# AE402FA0E5597BE0_CM55_HE_View register map
Vendor: Alif Semiconductor; Series: E4; File version: 1.0
CPU: CM55 r1p0, selectable endian, MPU, FPU, double-precision FPU, DSP, VTOR, 8 interrupt priority bits, 1 SAU regions
Registers are 32-bit, read-write, reset 0x0 unless marked. A register's access mark holds for its fields unless they carry their own. Offsets are from the block's base; [hi:lo] are bit positions; lines under a group give offsets from that group; {n}, {i} and the like mark numbered series; 'fields as' and 'values as' point back to an identical list.

## DMA2_SEC
Base 0x400C0000
Same registers: DMA2_NS 0x400E0000, DMA0_SEC 0x49080000, DMA0_NS 0x490A0000
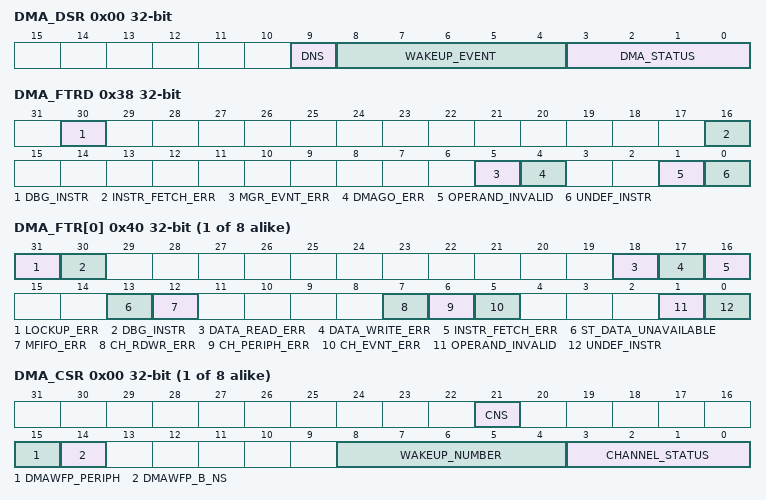
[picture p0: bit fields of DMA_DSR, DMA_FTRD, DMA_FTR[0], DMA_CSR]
0x00 DMA_DSR ro — DMA Manager Status Register
  [9] DNS — This bit provides the security status of the DMA manager thread.
    0=DMA manager operates in the secure state; 1=DMA manager operates in the non-secure state
  [8:4] WAKEUP_EVENT — When the DMA manager thread executes a DMAWFE instruction, it waits for the following event to occur:
    0=event[0]; 1=event[1]; 2=event[2]; 31=event[31]
  [3:0] DMA_STATUS — This bit field presents the operating state of the DMA manager. For more information, see Section Thread Operating States.
    0=Stopped; 1=Executing; 2=Cache miss; 3=Updating PC; 4=Waiting for event; 15=Faulting
0x04 DMA_DPC ro — DMA Program Counter Register
  [31:0] PC_MGR — Program counter for the DMA manager thread.
0x20 DMA_INTEN — Interrupt Enable Register
  [31:0] EVENT_IRQ_SELECT — Program the appropriate bit to control how the DMAC responds when it executes DMASEV. Bit [N] = 0x0: If the DMAC executes DMASEV for the event-interrupt resource N then the DMAC signals event N to all of the threads. Bit [N] = 0x1: If the DMAC executes DMASEV for the event-interrupt resource N then the DMAC sets IRQ[N] high. Note: For more information about selecting an event number, see Section DMASEV.
0x24 DMA_INT_EVENT_RIS ro — Event-Interrupt Raw Status Register
  [31:0] DMASEV_ACTIVE — This bit field returns the status of the event-interrupt resources. - Bit [N] = 0x0: Event N is inactive or IRQ[N] is low. - Bit [N] = 0x1: Event N is active or IRQ[N] is high. Note: When the DMAC executes a DMASEV N instruction to send event N, the DMA_INTEN register controls whether the DMAC: - Signals an interrupt using the appropriate IRQ. - Sends the event to all of the threads (see DMA_INTEN register). Note: The DMAC clears bit [N] when either: - The DMA_INTEN register is programmed to process the event and the DMAC executes a DMAWFE instruction for that event. - The DMA_INTEN register is programmed to signal an interrupt and the user write to the corresponding bit in the DMA_INTCLR register.
0x28 DMA_INTMIS ro — Interrupt Status Register
  [31:0] IRQ_STATUS — This bit field provides the status of the interrupts that are active in the DMAC. - Bit [N] = 0x0: Interrupt N is inactive and therefore IRQ[N] is low. - Bit [N] = 0x1: Interrupt N is active and therefore IRQ[N] is high. Note: User must use the DMA_INTCLR register to set bit [N] to 0x0. Note: Bit [N] is 0x0 if the DMA_INTEN register programs DMASEV to signal an event.
0x2C DMA_INTCLR wo — Interrupt Clear Register
  [31:0] IRQ_CLR — Controls the clearing of the IRQ outputs: - Bit [N] = 0x0: The status of IRQ[N] does not change. - Bit [N] = 0x1: The DMAC sets IRQ[N] low if the DMA_INTEN register programs the DMAC to signal an interrupt. Otherwise, the status of IRQ[N] does not change (see DMA_INTEN register).
0x30 DMA_FSRD ro — Fault Status DMA Manager Register
  [0] FS_MGR — This bit provides the fault status of the DMA manager. Refer to the DMA_FTRD register for more information about the type of fault that occured.
    0=The DMA manager thread is not in the Faulting state; 1=The DMA manager thread is in the Faulting state
0x34 DMA_FSRC ro — Fault Status DMA Channel Register
  [7:0] FAULT_STATUS — Each bit provides the fault status of the corresponding channel. - Bit [N] = 0x0: No fault is present on DMA channel N. - Bit [N] = 0x1: DMA channel N is in the Faulting or Faulting completing state. Refer to the DMA_FTRD register for more information about the type of fault that occured.
0x38 DMA_FTRD ro — Fault Type DMA Manager Register
  [30] DBG_INSTR — If the DMA manager aborts, this bit indicates whether the erroneous instruction was read from the system memory or from the debug interface.
    0=Instruction that generated an abort was read from system memory; 1=Instruction that generated an abort was read from the debug interface
  [16] INSTR_FETCH_ERR — This bit indicates the AXI response that the DMAC receives on the RRESP bus, after the DMA manager performs an instruction fetch.
    0=OKAY response; 1=EXOKAY, SLVERR, or DECERR response
  [5] MGR_EVNT_ERR — This bit indicates whether the DMA manager was attempting to execute DMAWFE or DMASEV with inappropriate security permissions.
    0=The DMA manager has appropriate security to execute DMAWFE or DMASEV; 1=The DMA manager thread in the non-secure state attempted to execute either: - DMAWFE to wait for a secure event. - DMASEV to create a secure event or secure interrupt.
  [4] DMAGO_ERR — This bit indicates whether the DMA manager was attempting to execute DMAGO with inappropriate security permissions.
    0=The DMA manager has appropriate security to execute DMAGO; 1=The DMA manager thread in the non-secure state attempted to execute DMAGO to create a DMA channel operating in the secure state
  [1] OPERAND_INVALID — This bit indicates whether the DMA manager was attempting to execute an instruction operand that was not valid for the configuration of the DMAC.
    0=Valid operand; 1=Invalid operand
  [0] UNDEF_INSTR — This bit indicates whether the DMA manager was attempting to execute an undefined instruction.
    0=Defined instruction; 1=Undefined instruction
{0x40+4i} DMA_FTR[{i}] (i=0..7) ro — Fault Type for DMA Channel (n) Register
  [31] LOCKUP_ERR — This bit indicates whether the DMA channel has locked-up because of resource starvation. This fault is an imprecise abort.
    0=DMA channel has adequate resources; 1=DMA channel has locked-up because of insufficient resources
  [30] DBG_INSTR — If the DMA channel aborts, this bit indicates whether the erroneous instruction was read from the system memory or from the debug interface. This fault is an imprecise abort but the bit is only valid when a precise abort occurs.
    values as DMA_FTRD.DBG_INSTR
  [18] DATA_READ_ERR — This bit indicates the AXI response that the DMAC receives on the RRESP bus, after the DMA channel thread performs a data read. This fault is an imprecise abort.
    0=OKAY response; 1=EXOKAY, SLVERR, or DECERR response
  [17] DATA_WRITE_ERR — This bit indicates the AXI response that the DMAC receives on the BRESP bus, after the DMA channel thread performs a data write. This fault is an imprecise abort.
    0=OKAY response; 1=EXOKAY, SLVERR, or DECERR response
  [16] INSTR_FETCH_ERR — This bit indicates the AXI response that the DMAC receives on the RRESP bus, after the DMA channel thread performs an instruction fetch. This fault is a precise abort.
    0=OKAY response; 1=EXOKAY, SLVERR, or DECERR response
  [13] ST_DATA_UNAVAILABLE — This bit indicates whether the MFIFO did not contain the data to enable the DMAC to perform the DMAST. This fault is a precise abort.
    0=MFIFO contains all the data to enable the DMAST to complete; 1=Previous DMALDs have not put enough data in the MFIFO to enable the DMAST to complete
  [12] MFIFO_ERR — This bit indicates whether the MFIFO prevented the DMA channel thread from executing DMALD or DMAST. Depending on the instruction: - DMALD 0x0: MFIFO contains sufficient space. 0x1: MFIFO is too small to hold the data that DMALD requires. - DMAST 0x0: MFIFO contains sufficient data. 0x1: MFIFO is too small to store the data to enable DMAST to complete. This fault is an imprecise abort.
  [7] CH_RDWR_ERR — This bit indicates whether a DMA channel thread, in the non-secure state, attempts to program the DMA_CCRn register to perform a secure read or secure write. This fault is a precise abort.
    0=A DMA channel thread in the non-secure state is not violating the security permissions; 1=A DMA channel thread in the non-secure state attempted to perform a secure read or secure write
  [6] CH_PERIPH_ERR — This bit indicates whether a DMA channel thread, in the non-secure state, attempts to execute DMAWFP, DMALDP, DMASTP, or DMAFLUSHP with inappropriate security permissions. This fault is a precise abort.
    0=A DMA channel thread in the non-secure state is not violating the security permissions; 1=A DMA channel thread in the non-secure state attempted to execute either: - DMAWFP to wait for a secure peripheral. - DMALDP or DMASTP to notify a secure peripheral. - DMAFLUSHP to flush a secure peripheral.
  [5] CH_EVNT_ERR — This bit indicates whether the DMA channel thread attempts to execute DMAWFE or DMASEV with inappropriate security permissions. This fault is a precise abort.
    0=A DMA channel thread in the non-secure state is not violating the security permissions; 1=A DMA channel thread in the non-secure state attempted to execute either: - DMAWFE to wait for a secure event. - DMASEV to create a secure event or secure interrupt.
  [1] OPERAND_INVALID — This bit indicates whether the DMA channel thread was attempting to execute an instruction operand that was not valid for the configuration of the DMAC. This fault is a precise abort.
    0=Valid operand; 1=Invalid operand
  [0] UNDEF_INSTR — This bit indicates whether the DMA channel thread was attempting to execute an undefined instruction. This fault is a precise abort.
    0=Defined instruction; 1=Undefined instruction
{0x100+8i} DMA_CHANNEL_RT_INFO[{i}] (i=0..7) group
  0x00 DMA_CSR ro — Channel Status for DMA Channel (n) Register
    [21] CNS — The channel non-secure bit provides the security of the DMA channel. Note: For more information, see Section DMAGO
      0=DMA channel operates in the secure state; 1=DMA channel operates in the non-secure state
    [15] DMAWFP_PERIPH — When the DMA channel thread executes DMAWFP, this bit indicates whether the periph operand was set. For more information, see Section DMAWFP.
      0=DMAWFP executed with the periph operand not set; 1=DMAWFP executed with the periph operand set
    [14] DMAWFP_B_NS — When the DMA channel thread executes DMAWFP, this bit indicates whether the burst or single operand were set. For more information, see Section DMAWFP.
      0=DMAWFP executed with the single operand set; 1=DMAWFP executed with the burst operand set
    [8:4] WAKEUP_NUMBER — If the DMA channel is in the Waiting for event state, or the Waiting for peripheral state, then these bits indicate the event or peripheral number that the channel is waiting for.
      0=DMA channel is waiting for event, or peripheral, 0; 1=DMA channel is waiting for event, or peripheral, 1; 2=DMA channel is waiting for event, or peripheral, 2; 31=DMA channel is waiting for event, or peripheral, 31
    [3:0] CHANNEL_STATUS — The channel status encoding is: For more information, see Section Thread Operating States.
      0=Stopped; 1=Executing; 2=Cache miss; 3=Updating PC; 4=Waiting for event; 5=At barrier; 7=Waiting for peripheral; 8=Killing; 9=Completing; 14=Faulting completing; 15=Faulting
  0x04 DMA_CPC ro — Channel PC for DMA Channel (n) Register
    [31:0] PC_CHNL — Program counter for the DMA channel n thread, where n depends on the address of the register.
{0x400+0x20*i} DMA_RT_CHANNEL_CFG[{i}] (i=0..7) group
  0x00 DMA_SAR ro — Source Address for DMA Channel (n) Register
    [31:0] SRC_ADDR — Address of the source data for DMA channel n, where n depends on the address of the register.
  0x04 DMA_DAR ro — Destination Address for DMA Channel (n) Register
    [31:0] DST_ADDR — Address for the destination data for DMA channel n, where n depends on the address of the register.
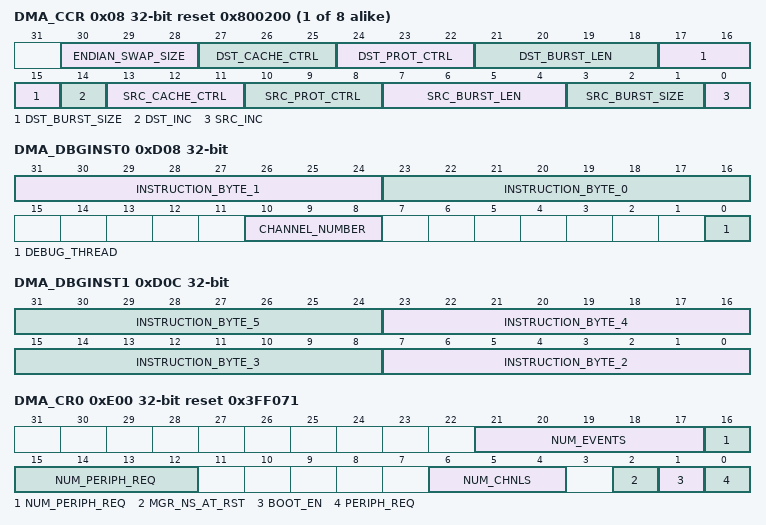
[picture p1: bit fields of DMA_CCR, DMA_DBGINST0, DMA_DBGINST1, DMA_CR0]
  0x08 DMA_CCR ro reset 0x800200 — Channel Control for DMA Channel (n) Register
    [30:28] ENDIAN_SWAP_SIZE — This bit field defines whether data can be swapped between little-endian (LE) and byte-invariant big-endian (BE-8) formats, and if so, also defines the natural width of the data independently of the source and destination transaction sizes. This enables unaligned data streams to use the full bus-width, and to be correctly transformed, irrespective of the source and destination address alignments. The format is identical to AxSIZE, except that 0x0 indicates that no swap must occur. For more information, see Section Endian Swap Size Restrictions.
      0=No swap, 8-bit data; 1=Swap bytes within 16-bit data; 2=Swap bytes within 32-bit data; 3=Swap bytes within 64-bit data; 4=Swap bytes within 128-bit data
    [27:25] DST_CACHE_CTRL — Programs the state of AWCACHE[3,1:0] a when the DMAC writes the destination data. - Bit [27] 0x0: AWCACHE[3] is low. 0x1: AWCACHE[3] is high. - Bit [26] 0x0: AWCACHE[1] is low. 0x1: AWCACHE[1] is high. - Bit [25] 0x0: AWCACHE[0] is low. 0x1: AWCACHE[0] is high. Note: AWCACHE[2] is tied low by the DMAC. Setting AWCACHE[3,1] = 0x2 violates the AXI protocol. See the AMBA AXI and ACE Protocol Specification.
    [24:22] DST_PROT_CTRL — Programs the state of AWPROT[2:0] when the DMAC writes the destination data. - Bit [24] 0x0: AWPROT[2] is low. 0x1: AWPROT[2] is high. - Bit [23] 0x0: AWPROT[1] is low. 0x1: AWPROT[1] is high. - Bit [22] 0x0: AWPROT[0] is low. 0x1: AWPROT[0] is high. Note: Only DMA channels in the secure state can program AWPROT[1] low, that is, a secure access. If a DMA channel in the non-secure state attempts to set AWPROT[1] low, then the DMA channel aborts.
    [21:18] DST_BURST_LEN — For each burst, these bits program the number of data transfers that the DMAC performs when it writes the destination data. The total number of bytes that the DMAC writes out of the MFIFO when it executes a DMAST instruction is the product of dst_burst_len and dst_burst_size. Note: These bits control the state of AWLEN[3:0].
      0=1 Data transfer; 1=2 Data transfers; 2=3 Data transfers; 15=16 Data transfers
    [17:15] DST_BURST_SIZE — For each beat within a burst, it programs the number of bytes that the DMAC writes to the destination. The total number of bytes that the DMAC writes out of the MFIFO when it executes a DMAST instruction is the product of dst_burst_len and dst_burst_size. Note: These bits control the state of AWSIZE[2:0].
      0=Writes 1 byte per beat; 1=Writes 2 bytes per beat; 2=Writes 4 bytes per beat; 3=Writes 8 bytes per beat; 4=Writes 16 bytes per beat
    [14] DST_INC — Programs the burst type that the DMAC performs when it writes the destination data.
      0=Fixed-address burst. The DMAC signals AWBURST[0] low.; 1=Incrementing-address burst. The DMAC signals AWBURST[0] high.
    [13:11] SRC_CACHE_CTRL — Set the bits to control the state of ARCACHE[2:0] when the DMAC reads the source data. - Bit [13] 0x0: ARCACHE[2] is low. 0x1: ARCACHE[2] is high. - Bit [12] 0x0: ARCACHE[1] is low. 0x1: ARCACHE[1] is high. - Bit [11] 0x0: ARCACHE[0] is low. 0x1: ARCACHE[0] is high. Note: The DMAC ties ARCACHE[3] low. Setting ARCACHE[2:1] = 0b10 violates the AXI protocol. See the AMBA AXI and ACE Protocol Specification.
    [10:8] SRC_PROT_CTRL — Programs the state of ARPROT[2:0] when the DMAC reads the source data. - Bit [10]: 0x0 = ARPROT[2] is low. 0x1 = ARPROT[2] is high. - Bit [9]: 0x0 = ARPROT[1] is low. 0x1 = ARPROT[1] is high. - Bit [8]: 0x0 = ARPROT[0] is low. 0x1 = ARPROT[0] is high. Note: Only DMA channels in the secure state can program ARPROT[1] low, that is, a secure access. If a DMA channel in the non-secure state attempts to set ARPROT[1] low, the DMA channel aborts.
    [7:4] SRC_BURST_LEN — For each burst, these bits program the number of data transfers that the DMAC performs when it reads the source data. The total number of bytes that the DMAC reads into the MFIFO when it executes a DMALD instruction is the product of SRC_BURST_LEN and SRC_BURST_SIZE bit fields. Note: These bits control the state of ARLEN[3:0].
      0=1 Data transfer; 1=2 Data transfers; 2=3 Data transfers; 7=16 Data transfers
    [3:1] SRC_BURST_SIZE — For each beat within a burst, it programs the number of bytes that the DMAC reads from the source. The total number of bytes that the DMAC reads into the MFIFO when it executes a DMALD instruction is the product of src_burst_len and src_burst_size. Note: These bits control the state of ARSIZE[2:0].
      0=Reads 1 byte per beat; 1=Reads 2 bytes per beat; 2=Reads 4 bytes per beat; 3=Reads 8 bytes per beat; 4=Reads 16 bytes per beat
    [0] SRC_INC — Programs the burst type that the DMAC performs when it reads the source data. Note: The DMAC does not generate: - Locked or exclusive accesses. - WRAP transfers. Therefore, ARBURST[1] and AWBURST[1] are always low.
      0=Fixed-address burst. The DMAC signals ARBURST[0] low.; 1=Incrementing-address burst. The DMAC signals ARBURST[0] high.
  0x0C DMA_LC0 ro — Loop Counter 0 for DMA Channel (n) Register
    [7:0] LOOP_COUNTER_ITERATIONS — The number of loop counter iterations.
  0x10 DMA_LC1 ro — Loop Counter 1 for DMA Channel (n) Register
    fields as DMA_RT_CHANNEL_CFG[0].DMA_LC0
0xD00 DMA_DBGSTATUS ro — Debug Status Register
  [0] DMA_DBGSTATUS — The debug status encoding is:
    0=Idle; 1=Busy
0xD04 DMA_DBGCMD wo — Debug Command Register
  [1:0] DMA_DBGCMD — The debug encoding is as follows:
    0=Execute the instruction that the DMA_DBGINST0 and DMA_DBGINST1 registers contain
0xD08 DMA_DBGINST0 wo — Debug Instruction Register 0
  [31:24] INSTRUCTION_BYTE_1
  [23:16] INSTRUCTION_BYTE_0
  [10:8] CHANNEL_NUMBER — DMA channel number: Note: When set to 0x1, this bit field selects the DMA channel to debug.
    0=DMA channel 0; 1=DMA channel 1; 2=DMA channel 2; 7=DMA channel 7
  [0] DEBUG_THREAD — The debug thread encoding is as follows:
    0=DMA manager thread; 1=DMA channel
0xD0C DMA_DBGINST1 wo — Debug Instruction Register 1
  [8n-9:8n-16] INSTRUCTION_BYTE_{n} (n=2..5)
0xE00 DMA_CR0 ro reset 0x3FF071 — Configuration Register 0
  [21:17] NUM_EVENTS — Number of interrupt outputs that the DMAC provides.
    31=32 interrupt outputs, IRQ[31:0]
  [16:12] NUM_PERIPH_REQ — Number of peripheral request interfaces that the DMAC provides.
    31=32 peripheral request interfaces
  [6:4] NUM_CHNLS — Number of DMA channels that the DMAC supports.
    7=8 DMA channels
  [2] MGR_NS_AT_RST — Indicates DMA manager is in the secure state when the DMAC exited from reset.
    0=DMA manager is in the secure state; 1=DMA manager is in the non-Secure state
  [1] BOOT_EN — Indicates the srunning state when the DMAC exited from reset.
    0=Stopped state and waits for an instruction from the Secure APB interface; 1=Running state
  [0] PERIPH_REQ — Supports peripheral requests.
    1=The DMAC provides the number of peripheral request interfaces that the NUM_PERIPH_REQ field specifies
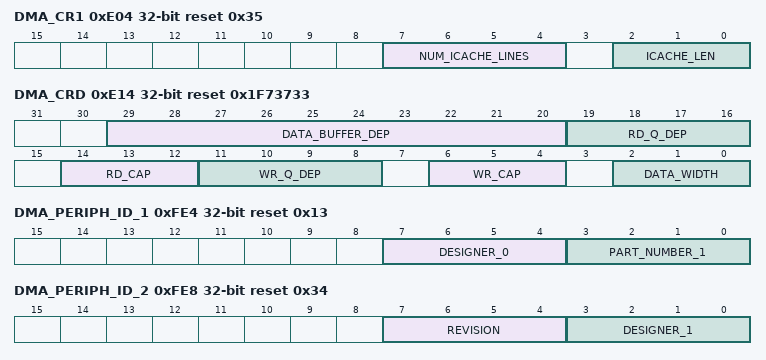
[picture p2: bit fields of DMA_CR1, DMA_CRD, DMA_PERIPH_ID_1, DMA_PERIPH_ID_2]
0xE04 DMA_CR1 ro reset 0x35 — Configuration Register 1
  [7:4] NUM_ICACHE_LINES — Number of an i-cache lines:
    3=4 i-cache lines
  [2:0] ICACHE_LEN — The length of an i-cache line:
    5=32 Bytes (8 words)
0xE08 DMA_CR2 ro — Configuration Register 2
  [31:0] BOOT_ADDR — This bit field provides the value of boot_addr[31:0] when the DMAC exits from reset.
0xE0C DMA_CR3 ro — Configuration Register 3
  [31:0] INS — Provides the security state of an event-interrupt resource. - Bit [N] = 0x0: Event<N> or irq[N] is in the secure state. - Bit [N] = 0x1: Event<N> or irq[N] is in the non-secure state.
0xE10 DMA_CR4 ro — Configuration Register 4
  [31:0] PNS — Provides the security state of the peripheral request interfaces. - Bit [N] = 0x0: Peripheral request interface N is in the secure state. - Bit [N] = 0x1: Peripheral request interface N is in the non-secure state.
0xE14 DMA_CRD ro reset 0x1F73733 — DMA Configuration Register
  [29:20] DATA_BUFFER_DEP — The number of the lines that the data buffer contains.
    31=32 lines
  [19:16] RD_Q_DEP — The depth of the read queue.
    7=8 lines
  [14:12] RD_CAP — Read issuing capability that programs the number of the outstanding read transactions.
    3=4 outstanding read transactions
  [11:8] WR_Q_DEP — The depth of the write queue.
    7=8 lines
  [6:4] WR_CAP — Write issuing capability that programs the number of the outstanding write transactions.
    3=4 outstanding write transactions
  [2:0] DATA_WIDTH — The data bus width of the AXI master interface.
    3=64-bit
0xE80 DMA_WD — Watchdog Register
  [0] WD_IRQ_ONLY — This bit controls how the DMAC responds when it detects a lock-up condition. For more information, see Section Watchdog Abort.
    0=The DMAC aborts all of the contributing DMA channels and sets IRQ_ABORT high; 1=The DMAC sets IRQ_ABORT high
0xFE0 DMA_PERIPH_ID_0 ro reset 0x30 — Peripheral ID Register 0
  [7:0] PART_NUMBER_0 — Part number 0 value
0xFE4 DMA_PERIPH_ID_1 ro reset 0x13 — Peripheral ID Register 1
  [7:4] DESIGNER_0 — Designer ID part 0
  [3:0] PART_NUMBER_1 — Part number value 1
0xFE8 DMA_PERIPH_ID_2 ro reset 0x34 — Peripheral ID Register 2
  [7:4] REVISION — Revision ID:
    0=r0p0; 1=r1p0; 2=r1p1; 3=r1p2
  [3:0] DESIGNER_1 — Designer ID part 1
0xFEC DMA_PERIPH_ID_3 ro — Peripheral ID Register 3
  [3:0] INTEGRATION_CFG — Indicates DMAC integration configuration
0xFF0 DMA_PCELL_ID_0 ro reset 0xD — Component Identification Register 0
  [7:0] PCELL_ID_0 — Component ID part 0
0xFF4 DMA_PCELL_ID_1 ro reset 0xF0 — Component Identification Register 1
  [7:0] PCELL_ID_1 — Component ID part 1
0xFF8 DMA_PCELL_ID_2 ro reset 0xD — Component Identification Register 2
  [7:0] PCELL_ID_2 — Component ID part 2
0xFFC DMA_PCELL_ID_3 ro reset 0xB1 — Component Identification Register 3
  [7:0] PCELL_ID_3 — Component ID part 3
